# LPC55S16 register map
Vendor: nxp.com; File version: 1.0
CPU: CM33 r2p0, little endian, MPU, FPU, VTOR, 3 interrupt priority bits
Registers are 32-bit, read-write, reset 0x0 unless marked. A register's access mark holds for its fields unless they carry their own. Offsets are from the block's base; [hi:lo] are bit positions; {n}, {i} and the like mark numbered series; 'fields as' and 'values as' point back to an identical list.

## PMC
Base 0x40020000
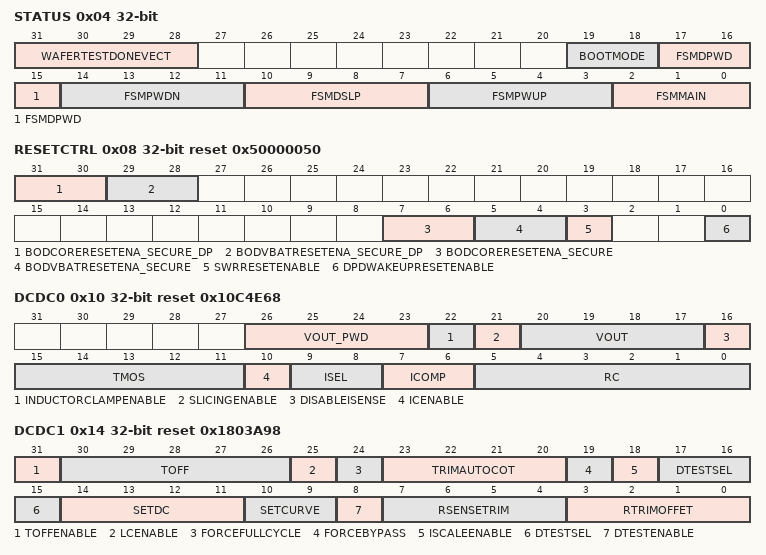
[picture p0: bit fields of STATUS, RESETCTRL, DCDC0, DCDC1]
0x04 STATUS — Power Management Controller FSM (Finite State Machines) status
  [31:28] WAFERTESTDONEVECT ro — Indicates cuurent status of wafer test level.
  [19:18] BOOTMODE ro — Latest IC Boot cause:.
    0=POWERUP (Latest IC boot was a Full power cycle boot sequence (PoR, Pin Reset, Brown Out Detectors Reset, Software Reset).); 1=DEEPSLEEP (Latest IC boot was from DEEP SLEEP low power mode..); 2=POWERDOWN (Latest IC boot was from POWER DOWN low power mode..); 3=DEEPPOWERDOWN (Latest IC boot was from DEEP POWER DOWN low power mode..)
  [17:15] FSMDPWD ro — DEEP POWER DOWN Finite State Machine (FSM) status.
  [14:11] FSMPWDN ro — POWER DOWN Finite State Machine (FSM) status.
  [10:7] FSMDSLP ro — DEEP SLEEP Finite State Machine (FSM) status.
  [6:3] FSMPWUP ro — POWER UP Finite State Machine (FSM) status.
  [2:0] FSMMAIN ro — Power Management Controller Main Finite State Machine (FSM) status.
    0=FSMMAIN_POWERUP (POWER UP : The IC is powering up.); 1=FSMMAIN_ACTIVE (ACTIVE : Power up is completed. The IC is in normal functional operation mode.); 2=FSMMAIN_POWERDOWN (POWER DOWN : the IC has entered POWER DOWN mode.); 3=FSMMAIN_DEEPSLEEP (DEEP SLEEP: The IC has entered DEEP SLEEP mode.); 6=FSMMAIN_DEEPPOWERDOWN (DEEP POWER DOWN : The IC entred DEEP POWER DOWN mode.); 7=FSMMAIN_DFT_ACTIVE (IC Structural TEST Mode : The IC has entered in IC Test mode.)
0x08 RESETCTRL reset 0x50000050 — Reset Control [Reset by: PoR, Pin Reset, Brown Out Detectors Reset, Deep Power Down Reset, Software Reset]
  [31:30] BODCORERESETENA_SECURE_DP — BOD Core reset enable.
    1=ENABLE (Any other value than b10, BOD Core reset is enable.); 2=DISABLE (BOD Core reset is disable.)
  [29:28] BODVBATRESETENA_SECURE_DP — BOD VBAT reset enable.
    1=ENABLE (Any other value than b10, BOD VBAT reset is enable.); 2=DISABLE (BOD VBAT reset is disable.)
  [7:6] BODCORERESETENA_SECURE — BOD Core reset enable.
    values as BODCORERESETENA_SECURE_DP
  [5:4] BODVBATRESETENA_SECURE — BOD VBAT reset enable.
    values as BODVBATRESETENA_SECURE_DP
  [3] SWRRESETENABLE — Software reset enable.
    0=DISABLE (Software reset is disable.); 1=ENABLE (Software reset is enable.)
  [0] DPDWAKEUPRESETENABLE — Wake-up from DEEP POWER DOWN reset event (either from wake up I/O or RTC or OS Event Timer).
    0=DISABLE (Reset event from DEEP POWER DOWN mode is disable.); 1=ENABLE (Reset event from DEEP POWER DOWN mode is enable.)
0x10 DCDC0 reset 0x10C4E68 — DCDC (first) control register [Reset by: PoR, Pin Reset, Brown Out Detectors Reset, Deep Power Down Reset, Software Reset]
  [26:23] VOUT_PWD — Set output regulation voltage during Deep Sleep.
  [22] INDUCTORCLAMPENABLE — Enable shorting of Inductor during PFM idle time.
  [21] SLICINGENABLE — Enable staggered switching of power switches.
  [20:17] VOUT — Set output regulation voltage.
    0=V_DCDC_0P950 (0.95 V.); 1=V_DCDC_0P975 (0.975 V.); 2=V_DCDC_1P000 (1 V.); 3=V_DCDC_1P025 (1.025 V.); 4=V_DCDC_1P050 (1.05 V.); 5=V_DCDC_1P075 (1.075 V.); 6=V_DCDC_1P100 (1.1 V.); 7=V_DCDC_1P125 (1.125 V.); 8=V_DCDC_1P150 (1.15 V.); 9=V_DCDC_1P175 (1.175 V.); 10=V_DCDC_1P200 (1.2 V.)
  [16] DISABLEISENSE — Disable Current sensing.
  [15:11] TMOS — One-shot generator reference current trimming signal.
  [10] ICENABLE — Selection of auto scaling of COT period with variations in VDD.
  [9:8] ISEL — Alter Internal biasing currents.
  [7:6] ICOMP — Select the type of ZCD comparator.
  [5:0] RC — Constant On-Time calibration.
0x14 DCDC1 reset 0x1803A98 — DCDC (second) control register [Reset by: PoR, Pin Reset, Brown Out Detectors Reset, Deep Power Down Reset, Software Reset]
  [31] TOFFENABLE — Enable Constant Off-Time feature.
  [30:26] TOFF — Constant Off-Time calibration input.
  [25] LCENABLE — Change the range of the peak detector of current inside the inductor.
  [24] FORCEFULLCYCLE — Force full PFM PMOS and NMOS cycle.
  [23:20] TRIMAUTOCOT — Change the scaling ratio of the feedforward compensation.
  [19] FORCEBYPASS — Force bypass mode.
  [18] ISCALEENABLE — Modify COT behavior.
  [17:15] DTESTSEL — Select the output signal for test.
  [14:11] SETDC — Bandgap calibration parameter.
  [10:9] SETCURVE — Bandgap calibration parameter.
  [8] DTESTENABLE — Enable Digital test signals.
  [7:4] RSENSETRIM — Adjust Max inductor peak current limiting.
  [3:0] RTRIMOFFET — Adjust the offset voltage of BJT based comparator.
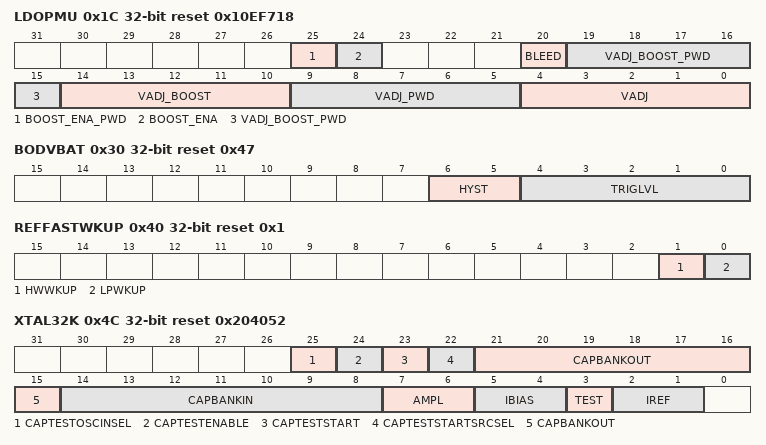
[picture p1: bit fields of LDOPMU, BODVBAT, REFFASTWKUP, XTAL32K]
0x1C LDOPMU reset 0x10EF718 — Power Management Unit (PMU) and Always-On domains LDO control [Reset by: PoR, Pin Reset, Brown Out Detectors Reset, Deep Power Down Reset, Software Reset]
  [25] BOOST_ENA_PWD — Control the LDO AO boost mode in the different low power modes (DEEP SLEEP, POWERDOWN, and DEEP POWER DOWN).
    0=DISABLE (LDO AO Boost Mode is disable.); 1=ENABLE (LDO AO Boost Mode is enable.)
  [24] BOOST_ENA — Control the LDO AO boost mode in ACTIVE mode.
    values as BOOST_ENA_PWD
  [20] BLEED — Controls LDOMEM bleed current.
    0=DISABLE (Bleed current is disable.); 1=ENABLE (Bleed current is enable.)
  [19:15] VADJ_BOOST_PWD — Sets the Always-On domain LDO Boost output level in all power down modes.
  [14:10] VADJ_BOOST — Sets the Always-On domain LDO Boost output level.
  [9:5] VADJ_PWD — Sets the Always-On domain LDO output level in all power down modes.
  [4:0] VADJ — Sets the Always-On domain LDO output level.
    0=V_1P220 (1.22 V.); 1=V_0P700 (0.7 V.); 2=V_0P725 (0.725 V.); 3=V_0P750 (0.75 V.); 4=V_0P775 (0.775 V.); 5=V_0P800 (0.8 V.); 6=V_0P825 (0.825 V.); 7=V_0P850 (0.85 V.); 8=V_0P875 (0.875 V.); 9=V_0P900 (0.9 V.); 10=V_0P960 (0.96 V.); 11=V_0P970 (0.97 V.); 12=V_0P980 (0.98 V.); 13=V_0P990 (0.99 V.); 14=V_1P000 (1 V.); 15=V_1P010 (1.01 V.); 16=V_1P020 (1.02 V.); 17=V_1P030 (1.03 V.); 18=V_1P040 (1.04 V.); 19=V_1P050 (1.05 V.); 20=V_1P060 (1.06 V.); 21=V_1P070 (1.07 V.); 22=V_1P080 (1.08 V.); 23=V_1P090 (1.09 V.); 24=V_1P100 (1.1 V.); 25=V_1P110 (1.11 V.); 26=V_1P120 (1.12 V.); 27=V_1P130 (1.13 V.); 28=V_1P140 (1.14 V.); 29=V_1P150 (1.15 V.); 30=V_1P160 (1.16 V.); 31=V_1P220_1 (1.22 V.)
0x30 BODVBAT reset 0x47 — VBAT Brown Out Dectector (BoD) control register [Reset by: PoR, Pin Reset, Software Reset]
  [6:5] HYST — BoD Hysteresis control.
    0=HYST_25MV (25 mV.); 1=HYST_50MV (50 mV.); 2=HYST_75MV (75 mV.); 3=HYST_100MV (100 mV.)
  [4:0] TRIGLVL — BoD trigger level.
    0=V_1P00 (1.00 V.); 1=V_1P10 (1.10 V.); 2=V_1P20 (1.20 V.); 3=V_1P30 (1.30 V.); 4=V_1P40 (1.40 V.); 5=V_1P50 (1.50 V.); 6=V_1P60 (1.60 V.); 7=V_1P65 (1.65 V.); 8=V_1P70 (1.70 V.); 9=V_1P75 (1.75 V.); 10=V_1P80 (1.80 V.); 11=V_1P90 (1.90 V.); 12=V_2P00 (2.00 V.); 13=V_2P10 (2.10 V.); 14=V_2P20 (2.20 V.); 15=V_2P30 (2.30 V.); 16=V_2P40 (2.40 V.); 17=V_2P50 (2.50 V.); 18=V_2P60 (2.60 V.); 19=V_2P70 (2.70 V.); 20=V_2P80 (2.806 V.); 21=V_2P90 (2.90 V.); 22=V_3P00 (3.00 V.); 23=V_3P10 (3.10 V.); 24=V_3P20 (3.20 V.); {v}=V_3P30_{v-23} (3.30 V.) (v=25..31)
0x40 REFFASTWKUP reset 0x1 — Analog References fast wake-up Control register [Reset by: PoR]
  [1] HWWKUP — Analog References fast wake-up in case of Hardware Pin reset: .
    0=DISABLE (Analog References fast wake-up feature is disabled in case of Hardware Pin reset.); 1=ENABLE (Analog References fast wake-up feature is enabled in case of Hardware Pin reset.)
  [0] LPWKUP — Analog References fast wake-up in case of wake-up from a low power mode (DEEP SLEEP, POWER DOWN and DEEP POWER DOWN): .
    0=DISABLE (Analog References fast wake-up feature is disabled in case of wake-up from any Low power mode.); 1=ENABLE (Analog References fast wake-up feature is enabled in case of wake-up from any Low power mode.)
0x4C XTAL32K reset 0x204052 — 32 KHz Crystal oscillator (XTAL) control register [Reset by: PoR, Brown Out Detectors Reset]
  [25] CAPTESTOSCINSEL — Select the input for test.
    0=OSCOUT (Oscillator output pin (osc_out).); 1=OSCIN (Oscillator input pin (osc_in).)
  [24] CAPTESTENABLE — Enable signal for cap test.
  [23] CAPTESTSTART — Start test.
  [22] CAPTESTSTARTSRCSEL — Source selection for xo32k_captest_start_ao_set.
    0=CAPSTART (Sourced from CAPTESTSTART.); 1=CALIB (Sourced from calibration.)
  [21:15] CAPBANKOUT — Capa bank setting output.
  [14:8] CAPBANKIN — Capa bank setting input.
  [7:6] AMPL — oscillator amplitude selection inputs.
  [5:4] IBIAS — bias current selection inputs.
  [3] TEST — Oscillator Test Mode.
  [2:1] IREF — reference output current selection inputs.
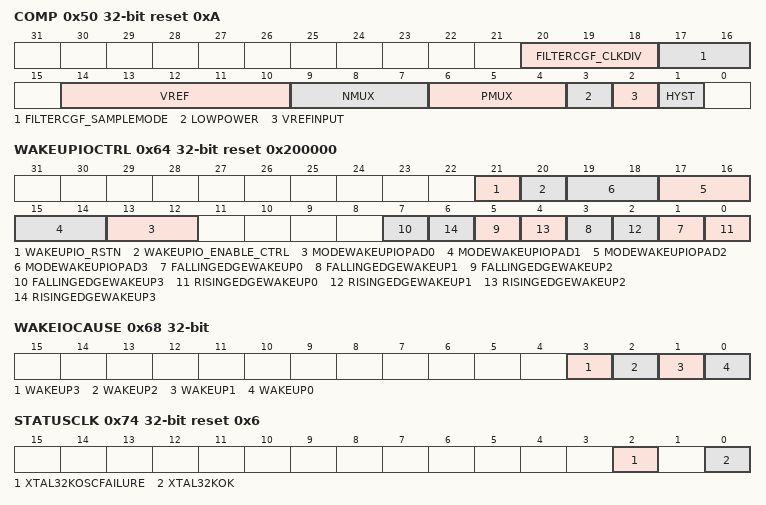
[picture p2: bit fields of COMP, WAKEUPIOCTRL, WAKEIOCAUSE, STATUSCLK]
0x50 COMP reset 0xA — Analog Comparator control register [Reset by: PoR, Pin Reset, Brown Out Detectors Reset, Deep Power Down Reset, Software Reset]
  [20:18] FILTERCGF_CLKDIV — Filter Clock divider.
    0=FILTER_1CLK_PERIOD (Filter clock period duration equals 1 Analog Comparator clock period.); 1=FILTER_2CLK_PERIOD (Filter clock period duration equals 2 Analog Comparator clock period.); 2=FILTER_4CLK_PERIOD (Filter clock period duration equals 4 Analog Comparator clock period.); 3=FILTER_8CLK_PERIOD (Filter clock period duration equals 8 Analog Comparator clock period.); 4=FILTER_16CLK_PERIOD (Filter clock period duration equals 16 Analog Comparator clock period.); 5=FILTER_32CLK_PERIOD (Filter clock period duration equals 32 Analog Comparator clock period.); 6=FILTER_64CLK_PERIOD (Filter clock period duration equals 64 Analog Comparator clock period.); 7=FILTER_128CLK_PERIOD (Filter clock period duration equals 128 Analog Comparator clock period.)
  [17:16] FILTERCGF_SAMPLEMODE — Control the filtering of the Analog Comparator output.
    0=BYPASS (Bypass mode.); 1=FILTER1CLK (Filter 1 clock period.); 2=FILTER2CLK (Filter 2 clock period.); 3=FILTER3CLK (Filter 3 clock period.)
  [14:10] VREF — Control reference voltage step, per steps of (VREFINPUT/31).
  [9:7] NMUX — Control word for N multiplexer:.
    0=VREF (VREF (See field VREFINPUT).); 1=CMP0_A (Pin P0_0.); 2=CMP0_B (Pin P0_9.); 3=CMP0_C (Pin P0_18.); 4=CMP0_D (Pin P1_14.); 5=CMP0_E (Pin P2_23.)
  [6:4] PMUX — Control word for P multiplexer:.
    0=VREF (VREF (See fiedl VREFINPUT).); 1=CMP0_A (Pin P0_0.); 2=CMP0_B (Pin P0_9.); 3=CMP0_C (Pin P0_18.); 4=CMP0_D (Pin P1_14.); 5=CMP0_E (Pin P2_23.)
  [3] LOWPOWER — Low power mode.
    0=HIGHSPEED (High speed mode.); 1=LOWSPEED (Low power mode (Low speed).)
  [2] VREFINPUT — Dedicated control bit to select between internal VREF and VDDA (for the resistive ladder).
    0=INTERNALREF (Select internal VREF.); 1=VDDA (Select VDDA.)
  [1] HYST — Hysteris when hyst = '1'.
    0=DISABLE (Hysteresis is disable.); 1=ENABLE (Hysteresis is enable.)
0x64 WAKEUPIOCTRL reset 0x200000 — Deep Power Down wake-up source [Reset by: PoR, Pin Reset, Software Reset]
  [21] WAKEUPIO_RSTN — WAKEUP IO event detector reset control.
    0=ASSERTED (Bloc is reset.); 1=RELEASED (Bloc is not reset.)
  [20] WAKEUPIO_ENABLE_CTRL — Enable WAKEUP IO PAD control from MODEWAKEUPIOPAD (bits 12 to 19).
    0=DISABLE (WAKEUP IO PAD mode control comes from IOCON.); 1=ENABLE (WAKEUP IO PAD mode control comes from MODEWAKEUPIOPAD (bits 12 to 19).)
  [2n+13:2n+12] MODEWAKEUPIOPAD{n} (n=0..3) — Selects function mode (on-chip pull-up/pull-down resistor control).
    0=INACTIVE (Inactive. Inactive (no pull-down/pull-up resistor enabled).); 1=PULL_DOWN (Pull-down. Pull-down resistor enabled.); 2=PULL_UP (Pull-up. Pull-up resistor enabled.); 3=REPEATER (Repeater. Repeater mode.)
  [2n+1] FALLINGEDGEWAKEUP{n} (n=0..3) — Enable / disable detection of falling edge events on Wake Up {n} pin in Deep Power Down modes:.
    0=DISABLE (Falling edge detection is disable.); 1=ENABLE (Falling edge detection is enable.)
  [2n] RISINGEDGEWAKEUP{n} (n=0..3) — Enable / disable detection of rising edge events on Wake Up {n} pin in Deep Power Down modes:.
    0=DISABLE (Rising edge detection is disable.); 1=ENABLE (Rising edge detection is enable.)
0x68 WAKEIOCAUSE — Allows to identify the Wake-up I/O source from Deep Power Down mode
  [3] WAKEUP3 — Allows to identify Wake up I/O 3 as the wake-up source from Deep Power Down mode.
    0=NOEVENT (Last wake up from Deep Power down mode was NOT triggred by wake up I/O 3.); 1=EVENT (Last wake up from Deep Power down mode was triggred by wake up I/O 3.)
  [2] WAKEUP2 — Allows to identify Wake up I/O 2 as the wake-up source from Deep Power Down mode.
    0=NOEVENT (Last wake up from Deep Power down mode was NOT triggred by wake up I/O 2.); 1=EVENT (Last wake up from Deep Power down mode was triggred by wake up I/O 2.)
  [1] WAKEUP1 — Allows to identify Wake up I/O 1 as the wake-up source from Deep Power Down mode.
    0=NOEVENT (Last wake up from Deep Power down mode was NOT triggred by wake up I/O 1.); 1=EVENT (Last wake up from Deep Power down mode was triggred by wake up I/O 1.)
  [0] WAKEUP0 ro — Allows to identify Wake up I/O 0 as the wake-up source from Deep Power Down mode.
    0=NOEVENT (Last wake up from Deep Power down mode was NOT triggred by wake up I/O 0.); 1=EVENT (Last wake up from Deep Power down mode was triggred by wake up I/O 0.)
0x74 STATUSCLK reset 0x6 — FRO and XTAL status register [Reset by: PoR, Brown Out Detectors Reset]
  [2] XTAL32KOSCFAILURE — XTAL32 KHZ oscillator oscillation failure detection indicator.
    0=NOFAIL (No oscillation failure has been detetced since the last time this bit has been cleared.); 1=FAILURE (At least one oscillation failure has been detetced since the last time this bit has been cleared.)
  [0] XTAL32KOK ro — XTAL oscillator 32 K OK signal.
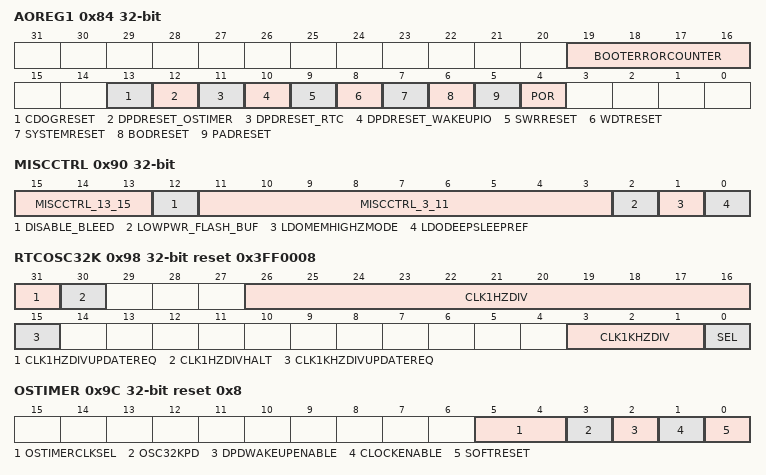
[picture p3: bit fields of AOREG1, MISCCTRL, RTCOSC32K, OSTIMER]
0x84 AOREG1 — General purpose always on domain data storage [Reset by: PoR, Brown Out Detectors Reset]
  [19:16] BOOTERRORCOUNTER — ROM Boot Fatal Error Counter.
  [13] CDOGRESET — The last chip reset was caused by the code Watchdog.
  [12] DPDRESET_OSTIMER — The last chip reset was caused by an OS Event Timer reset event during a Deep Power-Down mode.
  [11] DPDRESET_RTC — The last chip reset was caused by an RTC (either RTC Alarm or RTC wake up) reset event during a Deep Power-Down mode.
  [10] DPDRESET_WAKEUPIO — The last chip reset was caused by a Wake-up I/O reset event during a Deep Power-Down mode.
  [9] SWRRESET — The last chip reset was caused by a Software event.
  [8] WDTRESET — The last chip reset was caused by the Watchdog Timer.
  [7] SYSTEMRESET — The last chip reset was caused by a System Reset requested by the ARM CPU.
  [6] BODRESET — The last chip reset was caused by a Brown Out Detector (BoD), either VBAT BoD or Core Logic BoD.
  [5] PADRESET — The last chip reset was caused by a Pin Reset.
  [4] POR — The last chip reset was caused by a Power On Reset.
0x90 MISCCTRL — Dummy Control bus to PMU [Reset by: PoR, Pin Reset, Brown Out Detectors Reset, Deep Power Down Reset, Software Reset]
  [15:13] MISCCTRL_13_15 — Reserved.
  [12] DISABLE_BLEED — Controls LDO MEM bleed current. This field is expected to be controlled by the Low Power Software only in DEEP SLEEP low power mode.
    0=BLEED_ENABLE (LDO_MEM bleed current is enabled.); 1=BLEED_DISABLE (LDO_MEM bleed current is disabled. Should be set before entering in Deep Sleep low power mode and cleared after wake up from Deep SLeep low power mode.)
  [11:3] MISCCTRL_3_11 — Reserved.
  [2] LOWPWR_FLASH_BUF
  [1] LDOMEMHIGHZMODE — Control the activation of LDO MEM High Z mode.
    0=DISABLE (LDO MEM High Z mode is disabled.); 1=ENABLE (LDO MEM High Z mode is enabled.)
  [0] LDODEEPSLEEPREF — Select LDO Deep Sleep reference source.
    0=FLASHBUFFER (LDO DEEP Sleep uses Flash buffer biasing as reference.); 1=BGP0P8V (LDO DEEP Sleep uses Band Gap 0.8V as reference.)
0x98 RTCOSC32K reset 0x3FF0008 — RTC 1 KHZ and 1 Hz clocks source control register [Reset by: PoR, Brown Out Detectors Reset]
  [31] CLK1HZDIVUPDATEREQ — RTC 1Hz Divider status flag.
  [30] CLK1HZDIVHALT — Halts the divider counter.
  [26:16] CLK1HZDIV — Actual division ratio is : 31744 + CLK1HZDIV.
  [15] CLK1KHZDIVUPDATEREQ — RTC 1KHz clock Divider status flag.
  [3:1] CLK1KHZDIV — Actual division ratio is : 28 + CLK1KHZDIV.
  [0] SEL — Select the 32K oscillator to be used in Deep Power Down Mode for the RTC (either XTAL32KHz or FRO32KHz) .
    0=FRO32K (FRO 32 KHz.); 1=XTAL32K (XTAL 32KHz.)
0x9C OSTIMER reset 0x8 — OS Timer control register [Reset by: PoR, Brown Out Detectors Reset]
  [5:4] OSTIMERCLKSEL — OS event timer clock select.
    0=ENUM_0x0 (Oscillator 32 kHz clock.); 1=ENUM_0x1 (FRO 1MHz clock.); 2=ENUM_0x2 (Main clock for OS timer.); 3=ENUM_0x3 (No clock.)
  [3] OSC32KPD — Oscilator 32KHz (either FRO32KHz or XTAL32KHz according to RTCOSC32K.
  [2] DPDWAKEUPENABLE — Wake up enable in Deep Power Down mode (To be used in Enable Deep Power Down mode).
  [1] CLOCKENABLE — Enable OS event timer clock.
  [0] SOFTRESET — Active high reset.
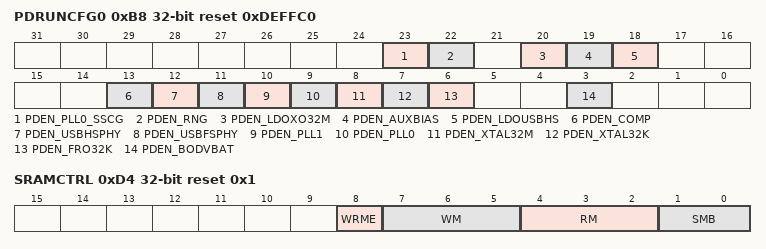
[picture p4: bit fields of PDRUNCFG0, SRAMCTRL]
0xB8 PDRUNCFG0 reset 0xDEFFC0 — Controls the power to various analog blocks [Reset by: PoR, Pin Reset, Brown Out Detectors Reset, Deep Power Down Reset, Software Reset]
  [23] PDEN_PLL0_SSCG — Controls power to System PLL (PLL0) Spread Spectrum module.
    0=POWEREDON (PLL0 Sread spectrum module is powered.); 1=POWEREDOFF (PLL0 Sread spectrum module is powered down.)
  [22] PDEN_RNG — Controls power to all True Random Number Genetaor (TRNG) clock sources.
    0=POWEREDON (TRNG clocks are powered.); 1=POWEREDOFF (TRNG clocks are powered down.)
  [20] PDEN_LDOXO32M — Controls power to high speed crystal LDO.
    0=POWEREDON (High speed crystal LDO is powered.); 1=POWEREDOFF (High speed crystal LDO is powered down.)
  [19] PDEN_AUXBIAS — Controls power to auxiliary biasing (AUXBIAS)
    0=POWEREDON (auxiliary biasing is powered.); 1=POWEREDOFF (auxiliary biasing is powered down.)
  [18] PDEN_LDOUSBHS — Controls power to USB high speed LDO.
    0=POWEREDON (USB high speed LDO is powered.); 1=POWEREDOFF (USB high speed LDO is powered down.)
  [13] PDEN_COMP — Controls power to Analog Comparator.
    0=POWEREDON (Analog Comparator is powered.); 1=POWEREDOFF (Analog Comparator is powered down.)
  [12] PDEN_USBHSPHY — Controls power to USB High Speed Phy.
    0=POWEREDON (USB HS phy is powered.); 1=POWEREDOFF (USB HS phy is powered down.)
  [11] PDEN_USBFSPHY — Controls power to USB Full Speed phy.
    0=POWEREDON (USB Full Speed phy is powered.); 1=POWEREDOFF (USB Full Speed phy is powered down.)
  [10] PDEN_PLL1 — Controls power to USB PLL (also refered as PLL1).
    0=POWEREDON (PLL1 is powered.); 1=POWEREDOFF (PLL1 is powered down.)
  [9] PDEN_PLL0 — Controls power to System PLL (also refered as PLL0).
    0=POWEREDON (PLL0 is powered.); 1=POWEREDOFF (PLL0 is powered down.)
  [8] PDEN_XTAL32M — Controls power to high speed crystal.
    0=POWEREDON (High speed crystal is powered.); 1=POWEREDOFF (High speed crystal is powered down.)
  [7] PDEN_XTAL32K — Controls power to crystal 32 KHz.
    0=POWEREDON (Crystal 32KHz is powered.); 1=POWEREDOFF (Crystal 32KHz is powered down.)
  [6] PDEN_FRO32K — Controls power to the Free Running Oscillator (FRO) 32 KHz.
    0=POWEREDON (FRO32KHz is powered.); 1=POWEREDOFF (FRO32KHz is powered down.)
  [3] PDEN_BODVBAT — Controls power to VBAT Brown Out Detector (BOD).
    0=POWEREDON (BOD VBAT is powered.); 1=POWEREDOFF (BOD VBAT is powered down.)
0xC0 PDRUNCFGSET0 wo — Controls the power to various analog blocks [Reset by: PoR, Pin Reset, Brown Out Detectors Reset, Deep Power Down Reset, Software Reset]
  [31:0] PDRUNCFGSET0 — Writing ones to this register sets the corresponding bit or bits in the PDRUNCFG0 register, if they are implemented.
0xC8 PDRUNCFGCLR0 wo — Controls the power to various analog blocks [Reset by: PoR, Pin Reset, Brown Out Detectors Reset, Deep Power Down Reset, Software Reset]
  [31:0] PDRUNCFGCLR0 — Writing ones to this register clears the corresponding bit or bits in the PDRUNCFG0 register, if they are implemented.
0xD4 SRAMCTRL reset 0x1 — All SRAMs common control signals [Reset by: PoR, Pin Reset, Brown Out Detectors Reset, Software Reset]
  [8] WRME — Write read margin enable.
  [7:5] WM — Write Margin control settings.
  [4:2] RM — Read Margin control settings.
  [1:0] SMB — Source Biasing voltage.
    0=LOW (Low leakage.); 1=MEDIUM (Medium leakage.); 2=HIGHEST (Highest leakage.); 3=DISABLE
